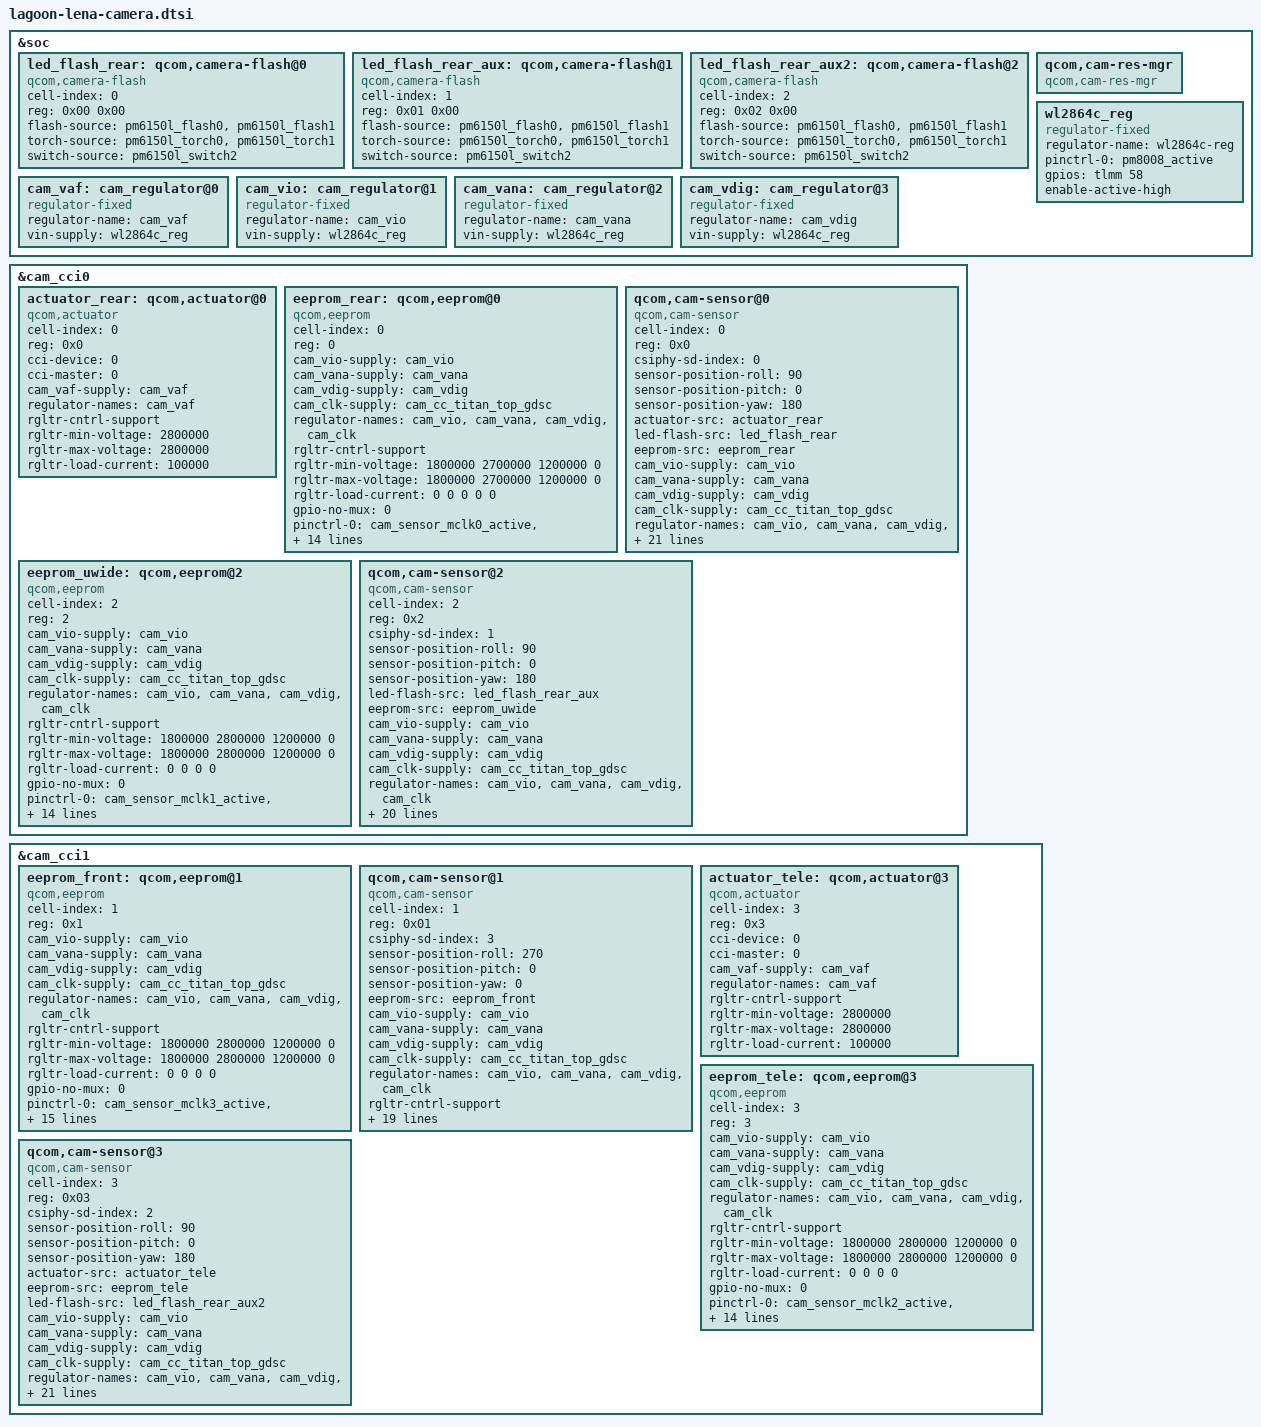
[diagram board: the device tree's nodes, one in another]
#include <dt-bindings/clock/qcom,camcc-lagoon.h>

&soc {
	led_flash_rear: qcom,camera-flash@0 {
		cell-index = <0>;
		reg = <0x00 0x00>;
		compatible = "qcom,camera-flash";
		flash-source = <&pm6150l_flash0 &pm6150l_flash1>;
		torch-source = <&pm6150l_torch0 &pm6150l_torch1>;
		switch-source = <&pm6150l_switch2>;
		status = "ok";
	};

	led_flash_rear_aux: qcom,camera-flash@1 {
		cell-index = <1>;
		reg = <0x01 0x00>;
		compatible = "qcom,camera-flash";
		flash-source = <&pm6150l_flash0 &pm6150l_flash1>;
		torch-source = <&pm6150l_torch0 &pm6150l_torch1>;
		switch-source = <&pm6150l_switch2>;
		status = "ok";
	};

	led_flash_rear_aux2: qcom,camera-flash@2 {
		cell-index = <2>;
		reg = <0x02 0x00>;
		compatible = "qcom,camera-flash";
		flash-source = <&pm6150l_flash0 &pm6150l_flash1>;
		torch-source = <&pm6150l_torch0 &pm6150l_torch1>;
		switch-source = <&pm6150l_switch2>;
		status = "ok";
	};

	qcom,cam-res-mgr {
		compatible = "qcom,cam-res-mgr";
		status = "ok";
	};

	// using default configuration
	wl2864c_reg: wl2864c_reg {
		compatible = "regulator-fixed";
		regulator-name = "wl2864c-reg";
		pinctrl-names = "default";
		pinctrl-0 = <&pm8008_active>;
		gpios = <&tlmm 58 GPIO_ACTIVE_HIGH>;
		enable-active-high;
	};

	// dummy regulators
	cam_vaf: cam_regulator@0 {
		compatible = "regulator-fixed";
		regulator-name = "cam_vaf";
		vin-supply = <&wl2864c_reg>;
	};

	cam_vio: cam_regulator@1 {
		compatible = "regulator-fixed";
		regulator-name = "cam_vio";
		vin-supply = <&wl2864c_reg>;
	};

	cam_vana: cam_regulator@2 {
		compatible = "regulator-fixed";
		regulator-name = "cam_vana";
		vin-supply = <&wl2864c_reg>;
	};

	cam_vdig: cam_regulator@3 {
		compatible = "regulator-fixed";
		regulator-name = "cam_vdig";
		vin-supply = <&wl2864c_reg>;
	};
};

&cam_cci0 {
	// wide camera
	actuator_rear: qcom,actuator@0 {
		cell-index = <0>;
		reg = <0x0>;
		compatible = "qcom,actuator";
		cci-device = <0>;
		cci-master = <0>;
		cam_vaf-supply = <&cam_vaf>;
		regulator-names = "cam_vaf";
		rgltr-cntrl-support;
		rgltr-min-voltage = <2800000>;
		rgltr-max-voltage = <2800000>;
		rgltr-load-current = <100000>;
		status = "ok";
	};

	eeprom_rear: qcom,eeprom@0 {
		cell-index = <0>;
		reg = <0>;
		compatible = "qcom,eeprom";
		cam_vio-supply = <&cam_vio>;
		cam_vana-supply = <&cam_vana>;
		cam_vdig-supply = <&cam_vdig>;
		cam_clk-supply = <&cam_cc_titan_top_gdsc>;
		regulator-names = "cam_vio", "cam_vana", "cam_vdig", "cam_clk"; 
		rgltr-cntrl-support;
		rgltr-min-voltage = <1800000 2700000 1200000 0>;
		rgltr-max-voltage = <1800000 2700000 1200000 0>;
		rgltr-load-current = <0 0 0 0 0>;
		gpio-no-mux = <0>;
		pinctrl-names = "cam_default", "cam_suspend";
		pinctrl-0 = <&cam_sensor_mclk0_active &cam_sensor_active_rear>;
		pinctrl-1 = <&cam_sensor_mclk0_suspend &cam_sensor_suspend_rear>;
		gpios = <&tlmm 29 0>, <&tlmm 34 0>;
		gpio-reset = <1>;
		gpio-req-tbl-num = <0 1>;
		gpio-req-tbl-flags = <1 0>;
		gpio-req-tbl-label = "CAMIF_MCLK0", "CAM_RESET0";
		sensor-mode = <0>;
		cci-device = <0>;
		cci-master = <0>;
		status = "ok";
		clocks = <&camcc CAM_CC_MCLK0_CLK>;
		clock-names = "cam_clk";
		clock-cntl-level = "turbo";
		clock-rates = <24000000>;
	};

	qcom,cam-sensor@0 {
		cell-index = <0>;
		compatible = "qcom,cam-sensor";
		reg = <0x0>;
		csiphy-sd-index = <0>;
		sensor-position-roll = <90>;
		sensor-position-pitch = <0>;
		sensor-position-yaw = <180>;
		actuator-src = <&actuator_rear>;
		led-flash-src = <&led_flash_rear>;
		eeprom-src = <&eeprom_rear>;
		cam_vio-supply = <&cam_vio>;
		cam_vana-supply = <&cam_vana>;
		cam_vdig-supply = <&cam_vdig>;
		cam_clk-supply = <&cam_cc_titan_top_gdsc>;
		regulator-names = "cam_vio", "cam_vana", "cam_vdig", "cam_clk";
		rgltr-cntrl-support;
		rgltr-min-voltage = <1800000 2700000 1200000 0>;
		rgltr-max-voltage = <1800000 2700000 1200000 0>;
		rgltr-load-current = <0 0 0 0>;
		gpio-no-mux = <0>;
		pinctrl-names = "cam_default", "cam_suspend";
		pinctrl-0 = <&cam_sensor_mclk0_active &cam_sensor_active_rear>;
		pinctrl-1 = <&cam_sensor_mclk0_suspend &cam_sensor_suspend_rear>;
		gpios = <&tlmm 29 0>, <&tlmm 34 0>;
		gpio-reset = <1>;
		gpio-req-tbl-num = <0 1>;
		gpio-req-tbl-flags = <1 0>;
		gpio-req-tbl-label = "CAMIF_MCLK0", "CAM_RESET0";
		sensor-mode = <0>;
		cci-device = <0>;
		cci-master = <0>;
		status = "ok";
		clocks = <&camcc CAM_CC_MCLK0_CLK>;
		clock-names = "cam_clk";
		clock-cntl-level = "turbo";
		clock-rates = <24000000>;
	};

	// uwide camera
	eeprom_uwide: qcom,eeprom@2 {
		cell-index = <2>;
		reg = <2>;
		compatible = "qcom,eeprom";
		cam_vio-supply = <&cam_vio>;
		cam_vana-supply = <&cam_vana>;
		cam_vdig-supply = <&cam_vdig>;
		cam_clk-supply = <&cam_cc_titan_top_gdsc>;
		regulator-names = "cam_vio", "cam_vana", "cam_vdig", "cam_clk";
		rgltr-cntrl-support;
		rgltr-min-voltage = <1800000 2800000 1200000 0>;
		rgltr-max-voltage = <1800000 2800000 1200000 0>;
		rgltr-load-current = <0 0 0 0>;
		gpio-no-mux = <0>;
		pinctrl-names = "cam_default", "cam_suspend";
		pinctrl-0 = <&cam_sensor_mclk1_active &cam_sensor_active_rear_aux>;
		pinctrl-1 = <&cam_sensor_mclk1_suspend &cam_sensor_suspend_rear_aux>;
		gpios = <&tlmm 30 0>, <&tlmm 35 0>;
		gpio-reset = <1>;
		gpio-req-tbl-num = <0 1>;
		gpio-req-tbl-flags = <1 0>;
		gpio-req-tbl-label = "CAMIF_MCLK1", "CAM_RESET1";
		sensor-mode = <0>;
		cci-device = <0>;
		cci-master = <1>;
		status = "ok";
		clocks = <&camcc CAM_CC_MCLK1_CLK>;
		clock-names = "cam_clk";
		clock-cntl-level = "turbo";
		clock-rates = <24000000>;
	};

	qcom,cam-sensor@2 {
		cell-index = <2>;
		compatible = "qcom,cam-sensor";
		reg = <0x2>;
		csiphy-sd-index = <1>;
		sensor-position-roll = <90>;
		sensor-position-pitch = <0>;
		sensor-position-yaw = <180>;
		led-flash-src = <&led_flash_rear_aux>;
		eeprom-src = <&eeprom_uwide>;
		cam_vio-supply = <&cam_vio>;
		cam_vana-supply = <&cam_vana>;
		cam_vdig-supply = <&cam_vdig>;
		cam_clk-supply = <&cam_cc_titan_top_gdsc>;
		regulator-names = "cam_vio", "cam_vana", "cam_vdig", "cam_clk";
		rgltr-cntrl-support;
		rgltr-min-voltage = <1800000 2800000 1200000 0>;
		rgltr-max-voltage = <1800000 2800000 1200000 0>;
		rgltr-load-current = <0 0 0 0>;
		gpio-no-mux = <0>;
		pinctrl-names = "cam_default", "cam_suspend";
		pinctrl-0 = <&cam_sensor_mclk1_active &cam_sensor_active_rear_aux>;
		pinctrl-1 = <&cam_sensor_mclk1_suspend &cam_sensor_suspend_rear_aux>;
		gpios = <&tlmm 30 0>, <&tlmm 35 0>;
		gpio-reset = <1>;
		gpio-req-tbl-num = <0 1>;
		gpio-req-tbl-flags = <1 0>;
		gpio-req-tbl-label = "CAMIF_MCLK1", "CAM_RESET1";
		sensor-mode = <0>;
		cci-device = <0>;
		cci-master = <1>;
		status = "ok";
		clocks = <&camcc CAM_CC_MCLK1_CLK>;
		clock-names = "cam_clk";
		clock-cntl-level = "turbo";
		clock-rates = <24000000>;
	};
};

&cam_cci1 {
	// front camera
	eeprom_front: qcom,eeprom@1 {
		cell-index = <1>;
		reg = <0x1>;
		compatible = "qcom,eeprom";
		cam_vio-supply = <&cam_vio>;
		cam_vana-supply = <&cam_vana>;
		cam_vdig-supply = <&cam_vdig>;
		cam_clk-supply = <&cam_cc_titan_top_gdsc>;
		regulator-names = "cam_vio", "cam_vana", "cam_vdig", "cam_clk";
		rgltr-cntrl-support;
		rgltr-min-voltage = <1800000 2800000 1200000 0>;
		rgltr-max-voltage = <1800000 2800000 1200000 0>;
		rgltr-load-current = <0 0 0 0>;
		gpio-no-mux = <0>;
		pinctrl-names = "cam_default", "cam_suspend";
		pinctrl-0 = <&cam_sensor_mclk3_active &cam_sensor_active_front>;
		pinctrl-1 = <&cam_sensor_mclk3_suspend &cam_sensor_suspend_front>;
		gpios = <&tlmm 32 0>, <&tlmm 37 0>;
		gpio-reset = <1>;
		gpio-req-tbl-num = <0 1>;
		gpio-req-tbl-flags = <1 0>;
		gpio-req-tbl-label = "CAMIF_MCLK3", "CAM_RESET3";
		sensor-position = <1>;
		sensor-mode = <0>;
		cci-device = <0>;
		cci-master = <1>;
		status = "ok";
		clocks = <&camcc CAM_CC_MCLK3_CLK>;
		clock-names = "cam_clk";
		clock-cntl-level = "turbo";
		clock-rates = <24000000>;
	};

	qcom,cam-sensor@1 {
		cell-index = <1>;
		compatible = "qcom,cam-sensor";
		reg = <0x01>;
		csiphy-sd-index = <3>;
		sensor-position-roll = <270>;
		sensor-position-pitch = <0>;
		sensor-position-yaw = <0>;
		eeprom-src = <&eeprom_front>;
		cam_vio-supply = <&cam_vio>;
		cam_vana-supply = <&cam_vana>;
		cam_vdig-supply = <&cam_vdig>;
		cam_clk-supply = <&cam_cc_titan_top_gdsc>;
		regulator-names = "cam_vio", "cam_vana", "cam_vdig", "cam_clk";
		rgltr-cntrl-support;
		rgltr-min-voltage = <1800000 2800000 1200000 0>;
		rgltr-max-voltage = <1800000 2800000 1200000 0>;
		rgltr-load-current = <0 0 0 0>;
		gpio-no-mux = <0>;
		pinctrl-names = "cam_default", "cam_suspend";
		pinctrl-0 = <&cam_sensor_mclk3_active &cam_sensor_active_front>;
		pinctrl-1 = <&cam_sensor_mclk3_suspend &cam_sensor_suspend_front>;
		gpios = <&tlmm 32 0>, <&tlmm 37 0>;
		gpio-reset = <1>;
		gpio-req-tbl-num = <0 1>;
		gpio-req-tbl-flags = <1 0>;
		gpio-req-tbl-label = "CAMIF_MCLK3", "CAM_RESET3";
		sensor-mode = <0>;
		cci-device = <0>;
		cci-master = <1>;
		status = "ok";
		clocks = <&camcc CAM_CC_MCLK3_CLK>;
		clock-names = "cam_clk";
		clock-cntl-level = "turbo";
		clock-rates = <24000000>;
	};

	// tele camera
	actuator_tele: qcom,actuator@3 {
		cell-index = <3>;
		reg = <0x3>;
		compatible = "qcom,actuator";
		cci-device = <0>;
		cci-master = <0>;
		cam_vaf-supply = <&cam_vaf>;
		regulator-names = "cam_vaf";
		rgltr-cntrl-support;
		rgltr-min-voltage = <2800000>;
		rgltr-max-voltage = <2800000>;
		rgltr-load-current = <100000>;
		status = "ok";
	};

	eeprom_tele: qcom,eeprom@3 {
		cell-index = <3>;
		reg = <3>;
		compatible = "qcom,eeprom";
		cam_vio-supply = <&cam_vio>;
		cam_vana-supply = <&cam_vana>;
		cam_vdig-supply = <&cam_vdig>;
		cam_clk-supply = <&cam_cc_titan_top_gdsc>;
		regulator-names = "cam_vio", "cam_vana", "cam_vdig", "cam_clk";
		rgltr-cntrl-support;
		rgltr-min-voltage = <1800000 2800000 1200000 0>;
		rgltr-max-voltage = <1800000 2800000 1200000 0>;
		rgltr-load-current = <0 0 0 0>;
		gpio-no-mux = <0>;
		pinctrl-names = "cam_default", "cam_suspend";
		pinctrl-0 = <&cam_sensor_mclk2_active &cam_sensor_active_rear_aux2>;
		pinctrl-1 = <&cam_sensor_mclk2_suspend &cam_sensor_suspend_rear_aux2>;
		gpios = <&tlmm 31 0>, <&tlmm 36 0>;
		gpio-reset = <1>;
		gpio-req-tbl-num = <0 1>;
		gpio-req-tbl-flags = <1 0>;
		gpio-req-tbl-label = "CAMIF_MCLK2", "CAM_RESET2";
		sensor-mode = <0>;
		cci-device = <0>;
		cci-master = <0>;
		status = "ok";
		clocks = <&camcc CAM_CC_MCLK2_CLK>;
		clock-names = "cam_clk";
		clock-cntl-level = "turbo";
		clock-rates = <24000000>;
	};

	qcom,cam-sensor@3 {
		cell-index = <3>;
		compatible = "qcom,cam-sensor";
		reg = <0x03>;
		csiphy-sd-index = <2>;
		sensor-position-roll = <90>;
		sensor-position-pitch = <0>;
		sensor-position-yaw = <180>;
		actuator-src = <&actuator_tele>;
		eeprom-src = <&eeprom_tele>;
		led-flash-src = <&led_flash_rear_aux2>;
		cam_vio-supply = <&cam_vio>;
		cam_vana-supply = <&cam_vana>;
		cam_vdig-supply = <&cam_vdig>;
		cam_clk-supply = <&cam_cc_titan_top_gdsc>;
		regulator-names = "cam_vio", "cam_vana", "cam_vdig", "cam_clk";
		rgltr-cntrl-support;
		rgltr-min-voltage = <1800000 2800000 1200000 0>;
		rgltr-max-voltage = <1800000 2800000 1200000 0>;
		rgltr-load-current = <0 0 0 0>;
		gpio-no-mux = <0>;
		pinctrl-names = "cam_default", "cam_suspend";
		pinctrl-0 = <&cam_sensor_mclk2_active &cam_sensor_active_rear_aux2>;
		pinctrl-1 = <&cam_sensor_mclk2_suspend &cam_sensor_suspend_rear_aux2>;
		gpios = <&tlmm 31 0>, <&tlmm 36 0>;
		gpio-reset = <1>;
		gpio-req-tbl-num = <0 1>;
		gpio-req-tbl-flags = <1 0>;
		gpio-req-tbl-label = "CAMIF_MCLK2", "CAM_RESET2";
		sensor-mode = <0>;
		cci-device = <0>;
		cci-master = <0>;
		status = "ok";
		clocks = <&camcc CAM_CC_MCLK2_CLK>;
		clock-names = "cam_clk";
		clock-cntl-level = "turbo";
		clock-rates = <24000000>;
	};
};
